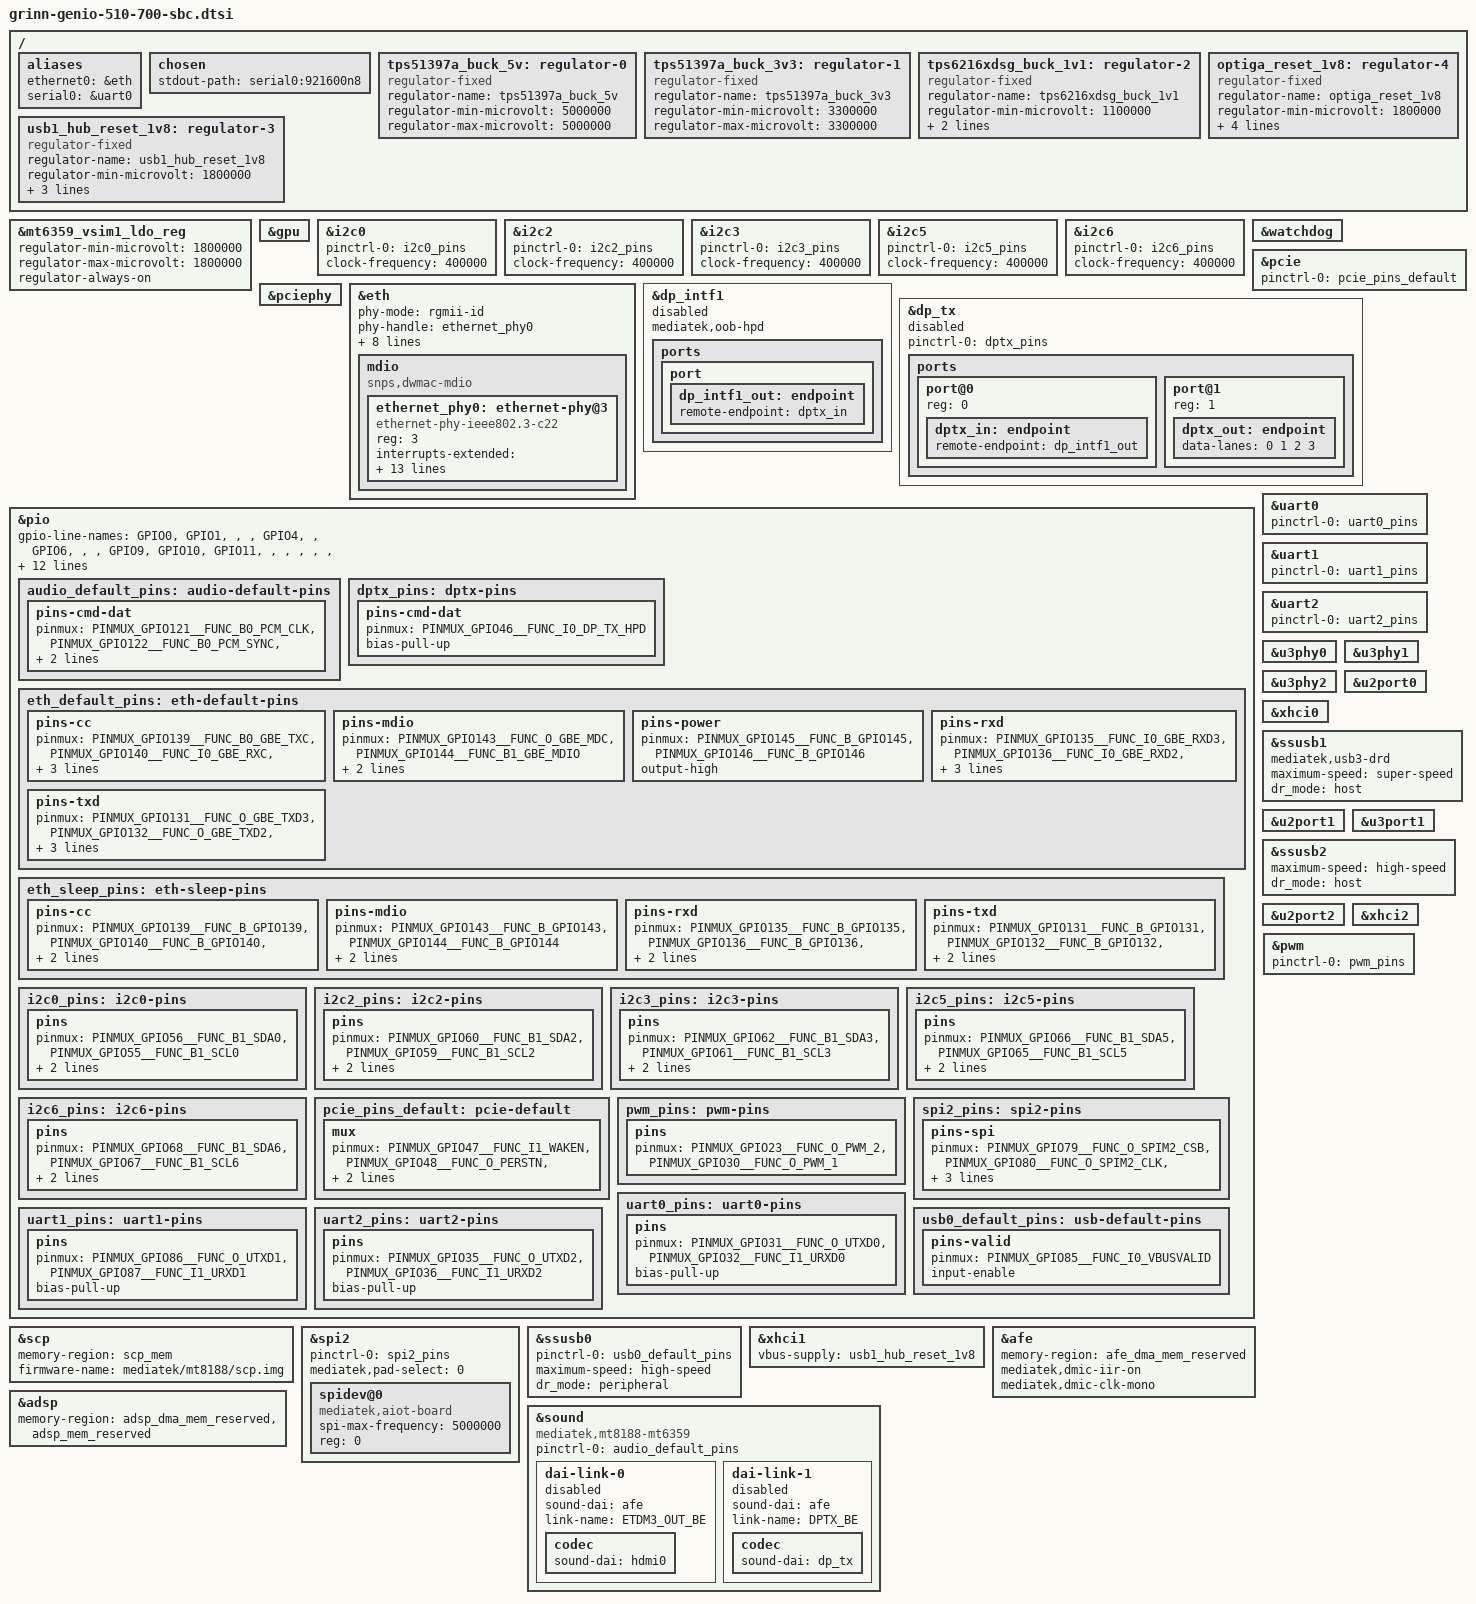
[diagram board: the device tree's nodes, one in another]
#include "grinn-genio-510-700-som.dtsi"
#include <dt-bindings/gpio/gpio.h>

/ {
	aliases {
		ethernet0 = &eth;
		serial0 = &uart0;
	};

	chosen {
		stdout-path = "serial0:921600n8";
	};

	tps51397a_buck_5v: regulator-0 {
		compatible = "regulator-fixed";
		regulator-name = "tps51397a_buck_5v";
		regulator-min-microvolt = <5000000>;
		regulator-max-microvolt = <5000000>;
	};

	tps51397a_buck_3v3: regulator-1 {
		compatible = "regulator-fixed";
		regulator-name = "tps51397a_buck_3v3";
		regulator-min-microvolt = <3300000>;
		regulator-max-microvolt = <3300000>;
	};

	tps6216xdsg_buck_1v1: regulator-2 {
		compatible = "regulator-fixed";
		regulator-name = "tps6216xdsg_buck_1v1";
		regulator-min-microvolt = <1100000>;
		regulator-max-microvolt = <1100000>;
		vin-supply = <&tps51397a_buck_5v>;
	};

	usb1_hub_reset_1v8: regulator-3 {
		compatible = "regulator-fixed";
		regulator-name = "usb1_hub_reset_1v8";
		regulator-min-microvolt = <1800000>;
		regulator-max-microvolt = <1800000>;
		gpio = <&pio 7 GPIO_ACTIVE_HIGH>; /* HUB_RESET */
		vin-supply = <&tps51397a_buck_3v3>;
	};

	optiga_reset_1v8: regulator-4 {
		compatible = "regulator-fixed";
		regulator-name = "optiga_reset_1v8";
		regulator-min-microvolt = <1800000>;
		regulator-max-microvolt = <1800000>;
		gpio = <&pio 167 GPIO_ACTIVE_HIGH>; /* OPTIGA_RESETn */
		enable-active-high;
		regulator-always-on;
	};
};

&mt6359_vsim1_ldo_reg {
	regulator-min-microvolt = <1800000>;
	regulator-max-microvolt = <1800000>;
	regulator-always-on;
};

&gpu {
	status = "okay";
};

&i2c0 {
	pinctrl-names = "default";
	pinctrl-0 = <&i2c0_pins>;
	clock-frequency = <400000>;
	status = "okay";
};

&i2c2 {
	pinctrl-names = "default";
	pinctrl-0 = <&i2c2_pins>;
	clock-frequency = <400000>;
	status = "okay";
};

&i2c3 {
	pinctrl-names = "default";
	pinctrl-0 = <&i2c3_pins>;
	clock-frequency = <400000>;
	status = "okay";
};

&i2c5 {
	pinctrl-names = "default";
	pinctrl-0 = <&i2c5_pins>;
	clock-frequency = <400000>;
	status = "okay";
};

&i2c6 {
	pinctrl-names = "default";
	pinctrl-0 = <&i2c6_pins>;
	clock-frequency = <400000>;
	status = "okay";
};

&watchdog {
	/delete-property/ mediatek,disable-extrst;
};

&pcie {
	pinctrl-names = "default";
	pinctrl-0 = <&pcie_pins_default>;
	status = "okay";
};

&pciephy {
	status = "okay";
};

&eth {
	phy-mode = "rgmii-id";
	phy-handle = <&ethernet_phy0>;
	snps,reset-active-low;
	snps,reset-delays-us = <0 11000 200000>;
	pinctrl-names = "default", "sleep";
	pinctrl-0 = <&eth_default_pins>;
	pinctrl-1 = <&eth_sleep_pins>;
	mediatek,mac-wol;
	mediatek,tx-delay-ps = <1740>;
	mediatek,rx-delay-ps = <0>;
	snps,reset-gpio = <&pio 147 GPIO_ACTIVE_LOW>;
	status = "okay";

	mdio {
		compatible = "snps,dwmac-mdio";
		#address-cells = <1>;
		#size-cells = <0>;

		ethernet_phy0: ethernet-phy@3 {
			compatible = "ethernet-phy-ieee802.3-c22";
			reg = <3>;
			interrupts-extended = <&pio 148 IRQ_TYPE_LEVEL_LOW>;
			rxc-skew-ps = <1500>;
			rxdv-skew-ps = <420>;
			rxd0-skew-ps = <420>;
			rxd1-skew-ps = <420>;
			rxd2-skew-ps = <420>;
			rxd3-skew-ps = <420>;
			txc-skew-ps = <900>;
			txen-skew-ps = <420>;
			txd0-skew-ps = <420>;
			txd1-skew-ps = <420>;
			txd2-skew-ps = <420>;
			txd3-skew-ps = <420>;
		};
	};
};

&dp_intf1 {
	status = "disabled";
	mediatek,oob-hpd;

	ports {
		port {
			dp_intf1_out: endpoint {
				remote-endpoint = <&dptx_in>;
			};
		};
	};
};

&dp_tx {
	pinctrl-names = "default";
	pinctrl-0 = <&dptx_pins>;
	status = "disabled";

	ports {
		#address-cells = <1>;
		#size-cells = <0>;

		port@0 {
			reg = <0>;

			dptx_in: endpoint {
				remote-endpoint = <&dp_intf1_out>;
			};
		};

		port@1 {
			reg = <1>;

			dptx_out: endpoint {
				data-lanes = <0 1 2 3>;
			};
		};
	};
};

&pio {
	gpio-line-names =
			  /* 0 - 4 */
			  "GPIO0", "GPIO1", "", "", "GPIO4",
			  /* 5 - 9 */
			  "", "GPIO6", "", "", "GPIO9",
			  /* 10 - 14 */
			  "GPIO10", "GPIO11", "", "", "",
			  /* 15 - 19 */
			  "", "", "", "", "",
			  /* 20 - 24 */
			  "", "GPIO21", "", "GPIO23_PWM2", "",
			  /* 25 - 29 */
			  "", "", "", "", "",
			  /* 30 - 34 */
			  "GPIO30_PWM1", "", "", "", "",
			  /* 35 - 39 */
			  "GPIO35_UART2_TXD", "GPIO36_UART2_RXD", "", "", "",
			  /* 40 - 44 */
			  "", "", "", "", "",
			  /* 45 - 49 */
			  "", "", "", "", "",
			  /* 50 - 54 */
			  "", "", "", "", "",
			  /* 55 - 59 */
			  "GPIO55_I2C0_SCL", "GPIO56_I2C0_SDA", "", "", "GPIO59_I2C2_SCL",
			  /* 60 - 64 */
			  "GPIO60_I2C2_SDA", "", "", "", "",
			  /* 65 - 69 */
			  "", "", "", "", "GPIO69",
			  /* 70 - 74 */
			  "", "", "GPIO72", "GPIO73", "GPIO74",
			  /* 75 - 79 */
			  "", "", "", "", "GPIO79_SPI2_CSn",
			  /* 80 - 84 */
			  "GPIO80_SPI2_CLK", "GPIO81_SPI2_MOSI", "GPIO82_SPI2_MISO", "", "",
			  /* 85 - 89 */
			  "", "", "", "", "",
			  /* 90 - 94 */
			  "", "", "", "", "",
			  /* 95 - 99 */
			  "", "", "", "", "",
			  /* 100 - 104 */
			  "", "", "", "", "",
			  /* 105 - 109 */
			  "", "", "", "", "",
			  /* 110 - 114 */
			  "", "", "", "", "",
			  /* 115 - 119 */
			  "", "", "", "", "",
			  /* 120 - 124 */
			  "", "GPIO121_PCM_CLK", "GPIO122_PCM_SYNC", "GPIO123_PCM_DO", "GPIO124_PCM_DI";

	audio_default_pins: audio-default-pins {
		pins-cmd-dat {
			pinmux = <PINMUX_GPIO121__FUNC_B0_PCM_CLK>,
				 <PINMUX_GPIO122__FUNC_B0_PCM_SYNC>,
				 <PINMUX_GPIO123__FUNC_O_PCM_DO>,
				 <PINMUX_GPIO124__FUNC_I0_PCM_DI>;
		};
	};

	dptx_pins: dptx-pins {
		pins-cmd-dat {
			pinmux = <PINMUX_GPIO46__FUNC_I0_DP_TX_HPD>;
			bias-pull-up;
		};
	};

	eth_default_pins: eth-default-pins {
		pins-cc {
			pinmux = <PINMUX_GPIO139__FUNC_B0_GBE_TXC>,
				 <PINMUX_GPIO140__FUNC_I0_GBE_RXC>,
				 <PINMUX_GPIO141__FUNC_I0_GBE_RXDV>,
				 <PINMUX_GPIO142__FUNC_O_GBE_TXEN>;
			drive-strength = <MTK_DRIVE_8mA>;
		};

		pins-mdio {
			pinmux = <PINMUX_GPIO143__FUNC_O_GBE_MDC>,
				 <PINMUX_GPIO144__FUNC_B1_GBE_MDIO>;
			drive-strength = <MTK_DRIVE_8mA>;
			input-enable;
		};

		pins-power {
			pinmux = <PINMUX_GPIO145__FUNC_B_GPIO145>,
				 <PINMUX_GPIO146__FUNC_B_GPIO146>;
			output-high;
		};

		pins-rxd {
			pinmux = <PINMUX_GPIO135__FUNC_I0_GBE_RXD3>,
				 <PINMUX_GPIO136__FUNC_I0_GBE_RXD2>,
				 <PINMUX_GPIO137__FUNC_I0_GBE_RXD1>,
				 <PINMUX_GPIO138__FUNC_I0_GBE_RXD0>;
			drive-strength = <MTK_DRIVE_8mA>;
		};

		pins-txd {
			pinmux = <PINMUX_GPIO131__FUNC_O_GBE_TXD3>,
				 <PINMUX_GPIO132__FUNC_O_GBE_TXD2>,
				 <PINMUX_GPIO133__FUNC_O_GBE_TXD1>,
				 <PINMUX_GPIO134__FUNC_O_GBE_TXD0>;
			drive-strength = <MTK_DRIVE_8mA>;
		};
	};

	eth_sleep_pins: eth-sleep-pins {
		pins-cc {
			pinmux = <PINMUX_GPIO139__FUNC_B_GPIO139>,
				 <PINMUX_GPIO140__FUNC_B_GPIO140>,
				 <PINMUX_GPIO141__FUNC_B_GPIO141>,
				 <PINMUX_GPIO142__FUNC_B_GPIO142>;
		};

		pins-mdio {
			pinmux = <PINMUX_GPIO143__FUNC_B_GPIO143>,
				 <PINMUX_GPIO144__FUNC_B_GPIO144>;
			input-disable;
			bias-disable;
		};

		pins-rxd {
			pinmux = <PINMUX_GPIO135__FUNC_B_GPIO135>,
				 <PINMUX_GPIO136__FUNC_B_GPIO136>,
				 <PINMUX_GPIO137__FUNC_B_GPIO137>,
				 <PINMUX_GPIO138__FUNC_B_GPIO138>;
		};

		pins-txd {
			pinmux = <PINMUX_GPIO131__FUNC_B_GPIO131>,
				 <PINMUX_GPIO132__FUNC_B_GPIO132>,
				 <PINMUX_GPIO133__FUNC_B_GPIO133>,
				 <PINMUX_GPIO134__FUNC_B_GPIO134>;
		};
	};

	i2c0_pins: i2c0-pins {
		pins {
			pinmux = <PINMUX_GPIO56__FUNC_B1_SDA0>,
				 <PINMUX_GPIO55__FUNC_B1_SCL0>;
			bias-pull-up = <MTK_PULL_SET_RSEL_011>;
			drive-strength-microamp = <1000>;
		};
	};

	i2c2_pins: i2c2-pins {
		pins {
			pinmux = <PINMUX_GPIO60__FUNC_B1_SDA2>,
				 <PINMUX_GPIO59__FUNC_B1_SCL2>;
			bias-pull-up = <MTK_PULL_SET_RSEL_011>;
			drive-strength-microamp = <1000>;
		};
	};

	i2c3_pins: i2c3-pins {
		pins {
			pinmux = <PINMUX_GPIO62__FUNC_B1_SDA3>,
				 <PINMUX_GPIO61__FUNC_B1_SCL3>;
			bias-pull-up = <MTK_PULL_SET_RSEL_011>;
			drive-strength-microamp = <1000>;
		};
	};

	i2c5_pins: i2c5-pins {
		pins {
			pinmux = <PINMUX_GPIO66__FUNC_B1_SDA5>,
				 <PINMUX_GPIO65__FUNC_B1_SCL5>;
			bias-pull-up = <MTK_PULL_SET_RSEL_011>;
			drive-strength-microamp = <1000>;
		};
	};

	i2c6_pins: i2c6-pins {
		pins {
			pinmux = <PINMUX_GPIO68__FUNC_B1_SDA6>,
				 <PINMUX_GPIO67__FUNC_B1_SCL6>;
			bias-pull-up = <MTK_PULL_SET_RSEL_011>;
			drive-strength-microamp = <1000>;
		};
	};

	pcie_pins_default: pcie-default {
		mux {
			pinmux = <PINMUX_GPIO47__FUNC_I1_WAKEN>,
				 <PINMUX_GPIO48__FUNC_O_PERSTN>,
				 <PINMUX_GPIO49__FUNC_B1_CLKREQN>;
			bias-pull-up;
		};
	};

	pwm_pins: pwm-pins {
		pins {
			pinmux = <PINMUX_GPIO23__FUNC_O_PWM_2>,
				 <PINMUX_GPIO30__FUNC_O_PWM_1>;
		};
	};

	spi2_pins: spi2-pins {
		pins-spi {
			pinmux = <PINMUX_GPIO79__FUNC_O_SPIM2_CSB>,
				 <PINMUX_GPIO80__FUNC_O_SPIM2_CLK>,
				 <PINMUX_GPIO81__FUNC_B0_SPIM2_MOSI>,
				 <PINMUX_GPIO82__FUNC_B0_SPIM2_MISO>;
			bias-disable;
		};
	};

	uart0_pins: uart0-pins {
		pins {
			pinmux = <PINMUX_GPIO31__FUNC_O_UTXD0>,
				 <PINMUX_GPIO32__FUNC_I1_URXD0>;
			bias-pull-up;
		};
	};

	uart1_pins: uart1-pins {
		pins {
			pinmux = <PINMUX_GPIO86__FUNC_O_UTXD1>,
				 <PINMUX_GPIO87__FUNC_I1_URXD1>;
			bias-pull-up;
		};
	};

	uart2_pins: uart2-pins {
		pins {
			pinmux = <PINMUX_GPIO35__FUNC_O_UTXD2>,
				 <PINMUX_GPIO36__FUNC_I1_URXD2>;
			bias-pull-up;
		};
	};

	usb0_default_pins: usb-default-pins {
		pins-valid {
			pinmux = <PINMUX_GPIO85__FUNC_I0_VBUSVALID>;
			input-enable;
		};
	};
};

&scp {
	memory-region = <&scp_mem>;
	status = "okay";
	firmware-name = "mediatek/mt8188/scp.img";
};

&uart0 {
	pinctrl-0 = <&uart0_pins>;
	pinctrl-names = "default";
	status = "okay";
};

&uart1 {
	pinctrl-0 = <&uart1_pins>;
	pinctrl-names = "default";
	status = "okay";
};

&uart2 {
	pinctrl-0 = <&uart2_pins>;
	pinctrl-names = "default";
	status = "okay";
};

&spi2 {
	pinctrl-0 = <&spi2_pins>;
	pinctrl-names = "default";
	mediatek,pad-select = <0>;
	#address-cells = <1>;
	#size-cells = <0>;
	status = "okay";

	spidev@0 {
		compatible = "mediatek,aiot-board";
		spi-max-frequency = <5000000>;
		reg = <0>;
	};
};

&u3phy0 {
	status = "okay";
};

&u3phy1 {
	status = "okay";
};

&u3phy2 {
	status = "okay";
};

&ssusb0 {
	pinctrl-0 = <&usb0_default_pins>;
	pinctrl-names = "default";
	maximum-speed = "high-speed";
	dr_mode = "peripheral";
	status = "okay";
};

&u2port0 {
	status = "okay";
};

&xhci0 {
	status = "okay";
};

&ssusb1 {
	mediatek,usb3-drd;
	maximum-speed = "super-speed";
	dr_mode = "host";
	status = "okay";	
};

&u2port1 {
	status = "okay";
};

&u3port1 {
	status = "okay";
};

&xhci1 {
	status = "okay";
	vbus-supply = <&usb1_hub_reset_1v8>;
};

&ssusb2 {
	maximum-speed = "high-speed";
	dr_mode = "host";
	status = "okay";
};

&u2port2 {
	status = "okay";
};

&xhci2 {
	status = "okay";
};

&afe {
	#sound-dai-cells = <0>;
	memory-region = <&afe_dma_mem_reserved>;
	mediatek,dmic-iir-on;
	mediatek,dmic-clk-mono;
	status = "okay";
};

&adsp {
	memory-region = <&adsp_dma_mem_reserved>,
			<&adsp_mem_reserved>;
};

&sound {
	compatible = "mediatek,mt8188-mt6359";
	pinctrl-names = "default";
	pinctrl-0 = <&audio_default_pins>;
	status = "okay";

	dai-link-0 {
		sound-dai = <&afe>;
		link-name = "ETDM3_OUT_BE";
		status = "disabled";

		codec {
			sound-dai = <&hdmi0>;
		};
	};

	dai-link-1 {
		sound-dai = <&afe>;
		link-name = "DPTX_BE";
		status = "disabled";

		codec {
			sound-dai = <&dp_tx>;
		};
	};
};

&pwm {
	pinctrl-0 = <&pwm_pins>;
	pinctrl-names = "default";
	status = "okay";
};
